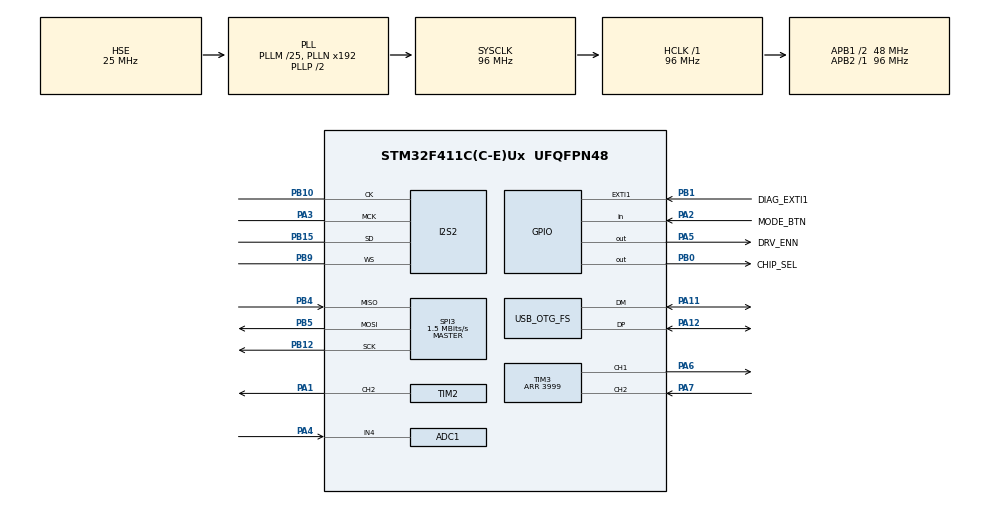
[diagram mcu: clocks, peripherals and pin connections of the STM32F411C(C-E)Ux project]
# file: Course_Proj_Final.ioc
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ADC1.Channel-0\#ChannelRegularConversion=ADC_CHANNEL_4
ADC1.NbrOfConversion=1
ADC1.NbrOfConversionFlag=1
ADC1.Rank-0\#ChannelRegularConversion=1
ADC1.SamplingTime-0\#ChannelRegularConversion=ADC_SAMPLETIME_84CYCLES
ADC1.master=1
Dma.Request0=SPI2_RX
Dma.SPI2_RX.0.Direction=DMA_PERIPH_TO_MEMORY
Dma.SPI2_RX.0.FIFOMode=DMA_FIFOMODE_DISABLE
Dma.SPI2_RX.0.Instance=DMA1_Stream3
Dma.SPI2_RX.0.MemDataAlignment=DMA_MDATAALIGN_HALFWORD
Dma.SPI2_RX.0.MemInc=DMA_MINC_ENABLE
Dma.SPI2_RX.0.Mode=DMA_CIRCULAR
Dma.SPI2_RX.0.PeriphDataAlignment=DMA_PDATAALIGN_HALFWORD
Dma.SPI2_RX.0.PeriphInc=DMA_PINC_DISABLE
Dma.SPI2_RX.0.Priority=DMA_PRIORITY_VERY_HIGH
I2S2.AudioFreq=I2S_AUDIOFREQ_16K
I2S2.DataFormat=I2S_DATAFORMAT_24B
I2S2.ErrorAudioFreq=-1.02 %
I2S2.FullDuplexMode=I2S_FULLDUPLEXMODE_DISABLE
I2S2.Instance=SPI$Index
I2S2.Mode=I2S_MODE_MASTER_RX
I2S2.RealAudioFreq=15.836 KHz
I2S2.VirtualMode=I2S_MODE_MASTER
Mcu.Family=STM32F4
Mcu.Name=STM32F411C(C-E)Ux
Mcu.Package=UFQFPN48
NVIC.ADC_IRQn=true\:0\:0\:false\:false\:true\:true\:true\:true
NVIC.DMA1_Stream3_IRQn=true\:0\:0\:false\:false\:true\:false\:true\:true
NVIC.OTG_FS_IRQn=true\:0\:0\:false\:false\:true\:false\:true\:true
NVIC.PriorityGroup=NVIC_PRIORITYGROUP_4
PA1.Signal=S_TIM2_CH2
PA11.Mode=Device_Only
PA11.Signal=USB_OTG_FS_DM
PA12.Mode=Device_Only
PA12.Signal=USB_OTG_FS_DP
PA13.Mode=Trace_Asynchronous_SW
PA13.Signal=SYS_JTMS-SWDIO
PA14.Mode=Trace_Asynchronous_SW
PA14.Signal=SYS_JTCK-SWCLK
PA2.GPIO_Label=MODE_BTN
PA2.GPIO_PuPd=GPIO_PULLUP
PA2.Signal=GPIO_Input
PA3.Mode=Master_Clock_Activated
PA3.Signal=I2S2_MCK
PA4.Signal=ADCx_IN4
PA5.GPIO_Label=DRV_ENN
PA5.PinState=GPIO_PIN_SET
PA5.Signal=GPIO_Output
PA6.Signal=S_TIM3_CH1
PA7.Signal=S_TIM3_CH2
PB0.GPIO_Label=CHIP_SEL
PB0.GPIO_Speed=GPIO_SPEED_FREQ_HIGH
PB0.PinState=GPIO_PIN_SET
PB0.Signal=GPIO_Output
PB1.GPIO_Label=DIAG_EXTI1
PB1.Signal=GPXTI1
PB10.Mode=Half_Duplex_Master
PB10.Signal=I2S2_CK
PB12.Mode=Full_Duplex_Master
PB12.Signal=SPI3_SCK
PB15.Mode=Half_Duplex_Master
PB15.Signal=I2S2_SD
PB3.Mode=Trace_Asynchronous_SW
PB3.Signal=SYS_JTDO-SWO
PB4.Mode=Full_Duplex_Master
PB4.Signal=SPI3_MISO
PB5.Mode=Full_Duplex_Master
PB5.Signal=SPI3_MOSI
PB9.Mode=Half_Duplex_Master
PB9.Signal=I2S2_WS
PH0\ -\ OSC_IN.Mode=HSE-External-Oscillator
PH0\ -\ OSC_IN.Signal=RCC_OSC_IN
PH1\ -\ OSC_OUT.Mode=HSE-External-Oscillator
PH1\ -\ OSC_OUT.Signal=RCC_OSC_OUT
ProjectManager.HeapSize=0x200
ProjectManager.StackSize=0x400
ProjectManager.TargetToolchain=STM32CubeIDE
RCC.48MHZClocksFreq_Value=48000000
RCC.AHBFreq_Value=96000000
RCC.APB1CLKDivider=RCC_HCLK_DIV2
RCC.APB1Freq_Value=48000000
RCC.APB1TimFreq_Value=96000000
RCC.APB2Freq_Value=96000000
RCC.APB2TimFreq_Value=96000000
RCC.CortexFreq_Value=96000000
RCC.HCLKFreq_Value=96000000
RCC.HSE_VALUE=25000000
RCC.HSI_VALUE=16000000
RCC.LSE_VALUE=32768
RCC.PLLM=25
RCC.SYSCLKFreq_VALUE=96000000
RCC.SYSCLKSource=RCC_SYSCLKSOURCE_PLLCLK
RCC.VCOOutputFreq_Value=192000000
SH.ADCx_IN4.0=ADC1_IN4,IN4
SH.S_TIM2_CH2.0=TIM2_CH2,PWM Generation2 CH2
SH.S_TIM3_CH1.0=TIM3_CH1,PWM Generation1 CH1
SH.S_TIM3_CH2.0=TIM3_CH2,Input_Capture2_from_TI2
SPI3.BaudRatePrescaler=SPI_BAUDRATEPRESCALER_32
SPI3.CLKPhase=SPI_PHASE_2EDGE
SPI3.CLKPolarity=SPI_POLARITY_HIGH
SPI3.CalculateBaudRate=1.5 MBits/s
SPI3.Direction=SPI_DIRECTION_2LINES
SPI3.Mode=SPI_MODE_MASTER
SPI3.VirtualType=VM_MASTER
TIM2.Channel-PWM\ Generation2\ CH2=TIM_CHANNEL_2
TIM2.Period=19999
TIM2.Prescaler=95
TIM2.Pulse-PWM\ Generation2\ CH2=1500
TIM3.Channel-Input_Capture2_from_TI2=TIM_CHANNEL_2
TIM3.Channel-PWM\ Generation1\ CH1=TIM_CHANNEL_1
TIM3.Period=3999
TIM3.Pulse-PWM\ Generation1\ CH1=2000
USB_DEVICE.CLASS_NAME_FS=CDC
USB_DEVICE.VirtualMode=Cdc
USB_DEVICE.VirtualModeFS=Cdc_FS
USB_OTG_FS.VirtualMode=Device_Only
VP_TIM2_VS_ClockSourceINT.Mode=Internal
VP_TIM3_VS_ClockSourceINT.Mode=Internal
VP_USB_DEVICE_VS_USB_DEVICE_CDC_FS.Mode=CDC_FS
board=custom

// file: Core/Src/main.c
/* USER CODE BEGIN Header */
/**
  ******************************************************************************
  * @file           : main.c
  * @brief          : Main program body
  ******************************************************************************
  * @attention
  *
  * Copyright (c) 2026 STMicroelectronics.
  * All rights reserved.
  *
  * This software is licensed under terms that can be found in the LICENSE file
  * in the root directory of this software component.
  * If no LICENSE file comes with this software, it is provided AS-IS.
  *
  ******************************************************************************
  */
/* USER CODE END Header */
#include "main.h"
#include "usb_device.h"

/* USER CODE BEGIN Includes */
#include "App.h"
/* USER CODE END Includes */

ADC_HandleTypeDef hadc1;

I2S_HandleTypeDef hi2s2;
DMA_HandleTypeDef hdma_spi2_rx;

SPI_HandleTypeDef hspi3;

TIM_HandleTypeDef htim2;
TIM_HandleTypeDef htim3;

void SystemClock_Config(void);
static void MX_GPIO_Init(void);
static void MX_DMA_Init(void);
static void MX_ADC1_Init(void);
static void MX_I2S2_Init(void);
static void MX_SPI3_Init(void);
static void MX_TIM2_Init(void);
static void MX_TIM3_Init(void);

int main(void)
{

  /* MCU Configuration--------------------------------------------------------*/

  /* Reset of all peripherals, Initializes the Flash interface and the Systick. */
  HAL_Init();

  /* Configure the system clock */
  SystemClock_Config();

  /* Initialize all configured peripherals */
  MX_GPIO_Init();
  MX_DMA_Init();
  MX_ADC1_Init();
  MX_I2S2_Init();
  MX_SPI3_Init();
  MX_TIM2_Init();
  MX_TIM3_Init();
  MX_USB_DEVICE_Init();
  /* USER CODE BEGIN 2 */
  App_Init();
  /* USER CODE END 2 */

  /* Infinite loop */
  while (1)
  {

    /* USER CODE BEGIN 3 */
	  App_Task();
  }
  /* USER CODE END 3 */
}

void SystemClock_Config(void)
{
  RCC_OscInitTypeDef RCC_OscInitStruct = {0};
  RCC_ClkInitTypeDef RCC_ClkInitStruct = {0};

  /** Configure the main internal regulator output voltage
  */
  __HAL_RCC_PWR_CLK_ENABLE();
  __HAL_PWR_VOLTAGESCALING_CONFIG(PWR_REGULATOR_VOLTAGE_SCALE1);

  /** Initializes the RCC Oscillators according to the specified parameters
  * in the RCC_OscInitTypeDef structure.
  */
  RCC_OscInitStruct.OscillatorType = RCC_OSCILLATORTYPE_HSE;
  RCC_OscInitStruct.HSEState = RCC_HSE_ON;
  RCC_OscInitStruct.PLL.PLLState = RCC_PLL_ON;
  RCC_OscInitStruct.PLL.PLLSource = RCC_PLLSOURCE_HSE;
  RCC_OscInitStruct.PLL.PLLM = 25;
  RCC_OscInitStruct.PLL.PLLN = 192;
  RCC_OscInitStruct.PLL.PLLP = RCC_PLLP_DIV2;
  RCC_OscInitStruct.PLL.PLLQ = 4;
  if (HAL_RCC_OscConfig(&RCC_OscInitStruct) != HAL_OK)
  {
    Error_Handler();
  }

  /** Initializes the CPU, AHB and APB buses clocks
  */
  RCC_ClkInitStruct.ClockType = RCC_CLOCKTYPE_HCLK|RCC_CLOCKTYPE_SYSCLK
                              |RCC_CLOCKTYPE_PCLK1|RCC_CLOCKTYPE_PCLK2;
  RCC_ClkInitStruct.SYSCLKSource = RCC_SYSCLKSOURCE_PLLCLK;
  RCC_ClkInitStruct.AHBCLKDivider = RCC_SYSCLK_DIV1;
  RCC_ClkInitStruct.APB1CLKDivider = RCC_HCLK_DIV2;
  RCC_ClkInitStruct.APB2CLKDivider = RCC_HCLK_DIV1;

  if (HAL_RCC_ClockConfig(&RCC_ClkInitStruct, FLASH_LATENCY_3) != HAL_OK)
  {
    Error_Handler();
  }
}

static void MX_ADC1_Init(void)
{

  ADC_ChannelConfTypeDef sConfig = {0};

  /** Configure the global features of the ADC (Clock, Resolution, Data Alignment and number of conversion)
  */
  hadc1.Instance = ADC1;
  hadc1.Init.ClockPrescaler = ADC_CLOCK_SYNC_PCLK_DIV4;
  hadc1.Init.Resolution = ADC_RESOLUTION_12B;
  hadc1.Init.ScanConvMode = DISABLE;
  hadc1.Init.ContinuousConvMode = DISABLE;
  hadc1.Init.DiscontinuousConvMode = DISABLE;
  hadc1.Init.ExternalTrigConvEdge = ADC_EXTERNALTRIGCONVEDGE_NONE;
  hadc1.Init.ExternalTrigConv = ADC_SOFTWARE_START;
  hadc1.Init.DataAlign = ADC_DATAALIGN_RIGHT;
  hadc1.Init.NbrOfConversion = 1;
  hadc1.Init.DMAContinuousRequests = DISABLE;
  hadc1.Init.EOCSelection = ADC_EOC_SINGLE_CONV;
  if (HAL_ADC_Init(&hadc1) != HAL_OK)
  {
    Error_Handler();
  }

  /** Configure for the selected ADC regular channel its corresponding rank in the sequencer and its sample time.
  */
  sConfig.Channel = ADC_CHANNEL_4;
  sConfig.Rank = 1;
  sConfig.SamplingTime = ADC_SAMPLETIME_84CYCLES;
  if (HAL_ADC_ConfigChannel(&hadc1, &sConfig) != HAL_OK)
  {
    Error_Handler();
  }

}

static void MX_I2S2_Init(void)
{

  hi2s2.Instance = SPI2;
  hi2s2.Init.Mode = I2S_MODE_MASTER_RX;
  hi2s2.Init.Standard = I2S_STANDARD_PHILIPS;
  hi2s2.Init.DataFormat = I2S_DATAFORMAT_24B;
  hi2s2.Init.MCLKOutput = I2S_MCLKOUTPUT_ENABLE;
  hi2s2.Init.AudioFreq = I2S_AUDIOFREQ_16K;
  hi2s2.Init.CPOL = I2S_CPOL_LOW;
  hi2s2.Init.ClockSource = I2S_CLOCK_PLL;
  hi2s2.Init.FullDuplexMode = I2S_FULLDUPLEXMODE_DISABLE;
  if (HAL_I2S_Init(&hi2s2) != HAL_OK)
  {
    Error_Handler();
  }

}

static void MX_SPI3_Init(void)
{

  /* SPI3 parameter configuration*/
  hspi3.Instance = SPI3;
  hspi3.Init.Mode = SPI_MODE_MASTER;
  hspi3.Init.Direction = SPI_DIRECTION_2LINES;
  hspi3.Init.DataSize = SPI_DATASIZE_8BIT;
  hspi3.Init.CLKPolarity = SPI_POLARITY_HIGH;
  hspi3.Init.CLKPhase = SPI_PHASE_2EDGE;
  hspi3.Init.NSS = SPI_NSS_SOFT;
  hspi3.Init.BaudRatePrescaler = SPI_BAUDRATEPRESCALER_32;
  hspi3.Init.FirstBit = SPI_FIRSTBIT_MSB;
  hspi3.Init.TIMode = SPI_TIMODE_DISABLE;
  hspi3.Init.CRCCalculation = SPI_CRCCALCULATION_DISABLE;
  hspi3.Init.CRCPolynomial = 10;
  if (HAL_SPI_Init(&hspi3) != HAL_OK)
  {
    Error_Handler();
  }

}

static void MX_TIM2_Init(void)
{

  TIM_ClockConfigTypeDef sClockSourceConfig = {0};
  TIM_MasterConfigTypeDef sMasterConfig = {0};
  TIM_OC_InitTypeDef sConfigOC = {0};

  htim2.Instance = TIM2;
  htim2.Init.Prescaler = 95;
  htim2.Init.CounterMode = TIM_COUNTERMODE_UP;
  htim2.Init.Period = 19999;
  htim2.Init.ClockDivision = TIM_CLOCKDIVISION_DIV1;
  htim2.Init.AutoReloadPreload = TIM_AUTORELOAD_PRELOAD_DISABLE;
  if (HAL_TIM_Base_Init(&htim2) != HAL_OK)
  {
    Error_Handler();
  }
  sClockSourceConfig.ClockSource = TIM_CLOCKSOURCE_INTERNAL;
  if (HAL_TIM_ConfigClockSource(&htim2, &sClockSourceConfig) != HAL_OK)
  {
    Error_Handler();
  }
  if (HAL_TIM_PWM_Init(&htim2) != HAL_OK)
  {
    Error_Handler();
  }
  sMasterConfig.MasterOutputTrigger = TIM_TRGO_RESET;
  sMasterConfig.MasterSlaveMode = TIM_MASTERSLAVEMODE_DISABLE;
  if (HAL_TIMEx_MasterConfigSynchronization(&htim2, &sMasterConfig) != HAL_OK)
  {
    Error_Handler();
  }
  sConfigOC.OCMode = TIM_OCMODE_PWM1;
  sConfigOC.Pulse = 1500;
  sConfigOC.OCPolarity = TIM_OCPOLARITY_HIGH;
  sConfigOC.OCFastMode = TIM_OCFAST_DISABLE;
  if (HAL_TIM_PWM_ConfigChannel(&htim2, &sConfigOC, TIM_CHANNEL_2) != HAL_OK)
  {
    Error_Handler();
  }
  HAL_TIM_MspPostInit(&htim2);

}

static void MX_TIM3_Init(void)
{

  TIM_ClockConfigTypeDef sClockSourceConfig = {0};
  TIM_MasterConfigTypeDef sMasterConfig = {0};
  TIM_OC_InitTypeDef sConfigOC = {0};
  TIM_IC_InitTypeDef sConfigIC = {0};

  htim3.Instance = TIM3;
  htim3.Init.Prescaler = 0;
  htim3.Init.CounterMode = TIM_COUNTERMODE_UP;
  htim3.Init.Period = 3999;
  htim3.Init.ClockDivision = TIM_CLOCKDIVISION_DIV1;
  htim3.Init.AutoReloadPreload = TIM_AUTORELOAD_PRELOAD_DISABLE;
  if (HAL_TIM_Base_Init(&htim3) != HAL_OK)
  {
    Error_Handler();
  }
  sClockSourceConfig.ClockSource = TIM_CLOCKSOURCE_INTERNAL;
  if (HAL_TIM_ConfigClockSource(&htim3, &sClockSourceConfig) != HAL_OK)
  {
    Error_Handler();
  }
  if (HAL_TIM_PWM_Init(&htim3) != HAL_OK)
  {
    Error_Handler();
  }
  if (HAL_TIM_IC_Init(&htim3) != HAL_OK)
  {
    Error_Handler();
  }
  sMasterConfig.MasterOutputTrigger = TIM_TRGO_RESET;
  sMasterConfig.MasterSlaveMode = TIM_MASTERSLAVEMODE_DISABLE;
  if (HAL_TIMEx_MasterConfigSynchronization(&htim3, &sMasterConfig) != HAL_OK)
  {
    Error_Handler();
  }
  sConfigOC.OCMode = TIM_OCMODE_PWM1;
  sConfigOC.Pulse = 2000;
  sConfigOC.OCPolarity = TIM_OCPOLARITY_HIGH;
  sConfigOC.OCFastMode = TIM_OCFAST_DISABLE;
  if (HAL_TIM_PWM_ConfigChannel(&htim3, &sConfigOC, TIM_CHANNEL_1) != HAL_OK)
  {
    Error_Handler();
  }
  sConfigIC.ICPolarity = TIM_INPUTCHANNELPOLARITY_RISING;
  sConfigIC.ICSelection = TIM_ICSELECTION_DIRECTTI;
  sConfigIC.ICPrescaler = TIM_ICPSC_DIV1;
  sConfigIC.ICFilter = 0;
  if (HAL_TIM_IC_ConfigChannel(&htim3, &sConfigIC, TIM_CHANNEL_2) != HAL_OK)
  {
    Error_Handler();
  }
  HAL_TIM_MspPostInit(&htim3);

}

static void MX_DMA_Init(void)
{

  /* DMA controller clock enable */
  __HAL_RCC_DMA1_CLK_ENABLE();

  /* DMA interrupt init */
  /* DMA1_Stream3_IRQn interrupt configuration */
  HAL_NVIC_SetPriority(DMA1_Stream3_IRQn, 0, 0);
  HAL_NVIC_EnableIRQ(DMA1_Stream3_IRQn);

}

static void MX_GPIO_Init(void)
{
  GPIO_InitTypeDef GPIO_InitStruct = {0};

  /* GPIO Ports Clock Enable */
  __HAL_RCC_GPIOH_CLK_ENABLE();
  __HAL_RCC_GPIOA_CLK_ENABLE();
  __HAL_RCC_GPIOB_CLK_ENABLE();

  /*Configure GPIO pin Output Level */
  HAL_GPIO_WritePin(DRV_ENN_GPIO_Port, DRV_ENN_Pin, GPIO_PIN_SET);

  /*Configure GPIO pin Output Level */
  HAL_GPIO_WritePin(CHIP_SEL_GPIO_Port, CHIP_SEL_Pin, GPIO_PIN_SET);

  /*Configure GPIO pin : MODE_BTN_Pin */
  GPIO_InitStruct.Pin = MODE_BTN_Pin;
  GPIO_InitStruct.Mode = GPIO_MODE_INPUT;
  GPIO_InitStruct.Pull = GPIO_PULLUP;
  HAL_GPIO_Init(MODE_BTN_GPIO_Port, &GPIO_InitStruct);

  /*Configure GPIO pin : DRV_ENN_Pin */
  GPIO_InitStruct.Pin = DRV_ENN_Pin;
  GPIO_InitStruct.Mode = GPIO_MODE_OUTPUT_PP;
  GPIO_InitStruct.Pull = GPIO_NOPULL;
  GPIO_InitStruct.Speed = GPIO_SPEED_FREQ_LOW;
  HAL_GPIO_Init(DRV_ENN_GPIO_Port, &GPIO_InitStruct);

  /*Configure GPIO pin : CHIP_SEL_Pin */
  GPIO_InitStruct.Pin = CHIP_SEL_Pin;
  GPIO_InitStruct.Mode = GPIO_MODE_OUTPUT_PP;
  GPIO_InitStruct.Pull = GPIO_NOPULL;
  GPIO_InitStruct.Speed = GPIO_SPEED_FREQ_HIGH;
  HAL_GPIO_Init(CHIP_SEL_GPIO_Port, &GPIO_InitStruct);

  /*Configure GPIO pin : DIAG_EXTI1_Pin */
  GPIO_InitStruct.Pin = DIAG_EXTI1_Pin;
  GPIO_InitStruct.Mode = GPIO_MODE_IT_RISING;
  GPIO_InitStruct.Pull = GPIO_NOPULL;
  HAL_GPIO_Init(DIAG_EXTI1_GPIO_Port, &GPIO_InitStruct);

}

void Error_Handler(void)
{
  __disable_irq();
  while (1)
  {
  }
}
